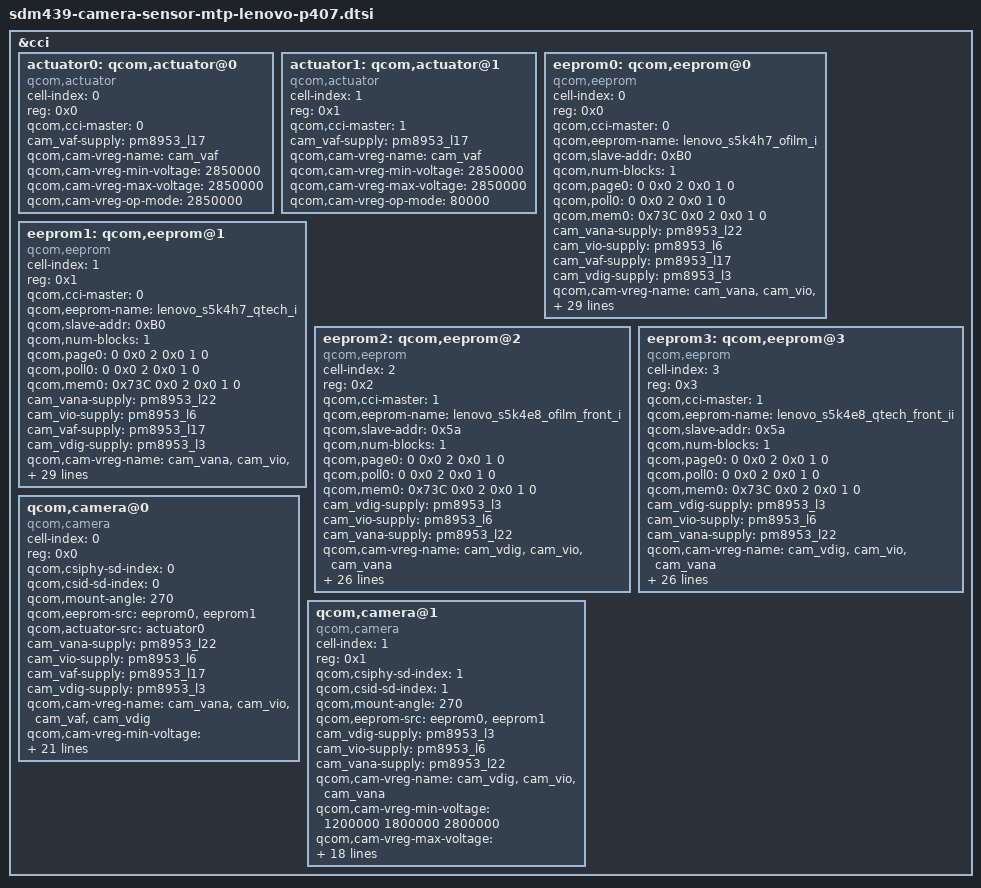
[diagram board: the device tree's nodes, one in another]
/*
 * Copyright (c) 2015-2016, 2018, The Linux Foundation. All rights reserved.
 *
 * This program is free software; you can redistribute it and/or modify
 * it under the terms of the GNU General Public License version 2 and
 * only version 2 as published by the Free Software Foundation.
 *
 * This program is distributed in the hope that it will be useful,
 * but WITHOUT ANY WARRANTY; without even the implied warranty of
 * MERCHANTABILITY or FITNESS FOR A PARTICULAR PURPOSE.  See the
 * GNU General Public License for more details.
 */

#include <dt-bindings/clock/msm-clocks-8952.h>

&cci {
	actuator0: qcom,actuator@0 {
		cell-index = <0>;
		reg = <0x0>;
		compatible = "qcom,actuator";
		qcom,cci-master = <0>;
		cam_vaf-supply = <&pm8953_l17>;
		qcom,cam-vreg-name = "cam_vaf";
		qcom,cam-vreg-min-voltage = <2850000>;
		qcom,cam-vreg-max-voltage = <2850000>;
		qcom,cam-vreg-op-mode = <2850000>;
	};

	actuator1: qcom,actuator@1 {
		cell-index = <1>;
		reg = <0x1>;
		compatible = "qcom,actuator";
		qcom,cci-master = <1>;
		cam_vaf-supply = <&pm8953_l17>;
		qcom,cam-vreg-name = "cam_vaf";
		qcom,cam-vreg-min-voltage = <2850000>;
		qcom,cam-vreg-max-voltage = <2850000>;
		qcom,cam-vreg-op-mode = <80000>;
	};

	eeprom0: qcom,eeprom@0 {
		cell-index = <0>;
		reg = <0x0>;
		compatible = "qcom,eeprom";
		qcom,cci-master = <0>;
		qcom,eeprom-name = "lenovo_s5k4h7_ofilm_i";
		qcom,slave-addr = <0xB0>;
		qcom,num-blocks = <1>;
		
		qcom,page0 = <0 0x0 2 0x0 1 0>;
		qcom,poll0 = <0 0x0 2 0x0 1 0>;
		qcom,mem0 = <0x73C 0x0 2 0x0 1 0>;
		cam_vana-supply = <&pm8953_l22>;
		cam_vio-supply = <&pm8953_l6>;
		cam_vaf-supply = <&pm8953_l17>;
		cam_vdig-supply = <&pm8953_l3>;
		qcom,cam-vreg-name = "cam_vana",
			"cam_vio", "cam_vaf", "cam_vdig";
		qcom,cam-vreg-min-voltage = <2800000 1800000 2850000 1200000>;
		qcom,cam-vreg-max-voltage = <2800000 1800000 2850000 1200000>;
		qcom,cam-vreg-op-mode = <280000 1800000 2850000 1200000>;
		pinctrl-names = "cam_default", "cam_suspend";
		pinctrl-0 = <&cam_sensor_mclk0_default
						&cam_sensor_rear_reset>;
		pinctrl-1 = <&cam_sensor_mclk0_sleep
						&cam_sensor_rear_reset_sleep>;
		gpios = <&tlmm 26 0>,
			<&tlmm 132 0>;
		qcom,gpio-reset = <1>;
		qcom,gpio-req-tbl-num = <0 1>;
		qcom,gpio-req-tbl-flags = <1 0>;
		qcom,gpio-req-tbl-label = "CAMIF_MCLK0",
			"CAM_RESET0";
		qcom,cam-power-seq-type = "sensor_gpio" ,"sensor_vreg", "sensor_vreg",
			"sensor_vreg", "sensor_vreg", "sensor_clk", "sensor_gpio";
		qcom,cam-power-seq-val = "sensor_gpio_reset", "cam_vio", "cam_vana", 
			"cam_vdig", "cam_vaf", "sensor_cam_mclk", "sensor_gpio_reset";
		qcom,cam-power-seq-cfg-val = <0 1 1 1 1 24000000 1>;
		qcom,cam-power-seq-delay = <1 1 1 1 1 1 2>;			
		status = "ok";
		clocks = <&clock_gcc clk_mclk0_clk_src>,
			<&clock_gcc clk_gcc_camss_mclk0_clk>;
		clock-names = "cam_src_clk", "cam_clk";
		qcom,clock-rates = <19200000 0>;
	};

	eeprom1: qcom,eeprom@1 {
		cell-index = <1>;
		reg = <0x1>;
		compatible = "qcom,eeprom";
		qcom,cci-master = <0>;
		qcom,eeprom-name = "lenovo_s5k4h7_qtech_i";
		qcom,slave-addr = <0xB0>;
		qcom,num-blocks = <1>;
		
		qcom,page0 = <0 0x0 2 0x0 1 0>;
		qcom,poll0 = <0 0x0 2 0x0 1 0>;
		qcom,mem0 = <0x73C 0x0 2 0x0 1 0>;
		cam_vana-supply = <&pm8953_l22>;
		cam_vio-supply = <&pm8953_l6>;
		cam_vaf-supply = <&pm8953_l17>;
		cam_vdig-supply = <&pm8953_l3>;
		qcom,cam-vreg-name = "cam_vana",
			"cam_vio", "cam_vaf", "cam_vdig";
		qcom,cam-vreg-min-voltage = <2800000 1800000 2850000 1200000>;
		qcom,cam-vreg-max-voltage = <2800000 1800000 2850000 1200000>;
		qcom,cam-vreg-op-mode = <280000 1800000 2850000 1200000>;
		pinctrl-names = "cam_default", "cam_suspend";
		pinctrl-0 = <&cam_sensor_mclk0_default
						&cam_sensor_rear_reset>;
		pinctrl-1 = <&cam_sensor_mclk0_sleep
						&cam_sensor_rear_reset_sleep>;
		gpios = <&tlmm 26 0>,
			<&tlmm 132 0>;
		qcom,gpio-reset = <1>;
		qcom,gpio-req-tbl-num = <0 1>;
		qcom,gpio-req-tbl-flags = <1 0>;
		qcom,gpio-req-tbl-label = "CAMIF_MCLK0",
			"CAM_RESET0";
		qcom,cam-power-seq-type = "sensor_gpio" ,"sensor_vreg", "sensor_vreg",
			"sensor_vreg", "sensor_vreg", "sensor_clk", "sensor_gpio";
		qcom,cam-power-seq-val = "sensor_gpio_reset", "cam_vio", "cam_vdig", 
			"cam_vana", "cam_vaf", "sensor_cam_mclk", "sensor_gpio_reset";
		qcom,cam-power-seq-cfg-val = <0 1 1 1 1 24000000 1>;
		qcom,cam-power-seq-delay = <1 1 1 1 1 1 2>;			
		status = "ok";
		clocks = <&clock_gcc clk_mclk0_clk_src>,
			<&clock_gcc clk_gcc_camss_mclk0_clk>;
		clock-names = "cam_src_clk", "cam_clk";
		qcom,clock-rates = <19200000 0>;
	};	

//start add front camera by chenbaicheng 20190124
	eeprom2: qcom,eeprom@2 {
		cell-index = <2>;
		reg = <0x2>;
		compatible = "qcom,eeprom";
		qcom,cci-master = <1>;
		qcom,eeprom-name = "lenovo_s5k4e8_ofilm_front_i";
		qcom,slave-addr = <0x5a>;
		qcom,num-blocks = <1>;
		
		qcom,page0 = <0 0x0 2 0x0 1 0>;
		qcom,poll0 = <0 0x0 2 0x0 1 0>;
		qcom,mem0 = <0x73C 0x0 2 0x0 1 0>;

		cam_vdig-supply = <&pm8953_l3>;
		cam_vio-supply = <&pm8953_l6>;
		cam_vana-supply = <&pm8953_l22>;
		qcom,cam-vreg-name = "cam_vdig", "cam_vio", "cam_vana";
		qcom,cam-vreg-min-voltage = <1200000 1800000 2800000>;
		qcom,cam-vreg-max-voltage = <1200000 1800000 2800000>;
		qcom,cam-vreg-op-mode = <200000 0 80000>;
		pinctrl-names = "cam_default", "cam_suspend";
		pinctrl-0 = <&cam_sensor_mclk1_default
				&cam_sensor_front_default>;
		pinctrl-1 = <&cam_sensor_mclk1_sleep
				&cam_sensor_front_sleep>;
		gpios = <&tlmm 27 0>,
			<&tlmm 38 0>;
		qcom,gpio-reset = <1>;
		qcom,gpio-req-tbl-num = <0 1>;
		qcom,gpio-req-tbl-flags = <1 0>;
		qcom,gpio-req-tbl-label = "CAMIF_MCLK1",
			"CAM_RESET1";
		qcom,cam-power-seq-type = "sensor_gpio" ,"sensor_vreg", "sensor_vreg",
			"sensor_vreg", "sensor_clk", "sensor_gpio";
		qcom,cam-power-seq-val = "sensor_gpio_reset", "cam_vio", "cam_vdig", 
			"cam_vana", "sensor_cam_mclk", "sensor_gpio_reset";
		qcom,cam-power-seq-cfg-val = <0 1 1 1 24000000 1>;
		qcom,cam-power-seq-delay = <1 5 5 5 1 10>;			
		status = "ok";
		clocks = <&clock_gcc clk_mclk1_clk_src>,
			<&clock_gcc clk_gcc_camss_mclk1_clk>;
		clock-names = "cam_src_clk", "cam_clk";
		qcom,clock-rates = <24000000 0>;
	};

	eeprom3: qcom,eeprom@3 {
		cell-index = <3>;
		reg = <0x3>;
		compatible = "qcom,eeprom";
		qcom,cci-master = <1>;
		qcom,eeprom-name = "lenovo_s5k4e8_qtech_front_ii";
		qcom,slave-addr = <0x5a>;
		qcom,num-blocks = <1>;
		
		qcom,page0 = <0 0x0 2 0x0 1 0>;
		qcom,poll0 = <0 0x0 2 0x0 1 0>;
		qcom,mem0 = <0x73C 0x0 2 0x0 1 0>;

		cam_vdig-supply = <&pm8953_l3>;
		cam_vio-supply = <&pm8953_l6>;
		cam_vana-supply = <&pm8953_l22>;
		qcom,cam-vreg-name = "cam_vdig", "cam_vio", "cam_vana";
		qcom,cam-vreg-min-voltage = <1200000 1800000 2800000>;
		qcom,cam-vreg-max-voltage = <1200000 1800000 2800000>;
		qcom,cam-vreg-op-mode = <200000 0 80000>;
		pinctrl-names = "cam_default", "cam_suspend";
		pinctrl-0 = <&cam_sensor_mclk1_default
				&cam_sensor_front_default>;
		pinctrl-1 = <&cam_sensor_mclk1_sleep
				&cam_sensor_front_sleep>;
		gpios = <&tlmm 27 0>,
			<&tlmm 38 0>;
		qcom,gpio-reset = <1>;
		qcom,gpio-req-tbl-num = <0 1>;
		qcom,gpio-req-tbl-flags = <1 0>;
		qcom,gpio-req-tbl-label = "CAMIF_MCLK1",
			"CAM_RESET1";
		qcom,cam-power-seq-type = "sensor_gpio" ,"sensor_vreg", "sensor_vreg",
			"sensor_vreg", "sensor_clk", "sensor_gpio";
		qcom,cam-power-seq-val = "sensor_gpio_reset", "cam_vio", "cam_vdig", 
			"cam_vana", "sensor_cam_mclk", "sensor_gpio_reset";
		qcom,cam-power-seq-cfg-val = <0 1 1 1 24000000 1>;
		qcom,cam-power-seq-delay = <1 5 5 5 1 10>;			
		status = "ok";
		clocks = <&clock_gcc clk_mclk1_clk_src>,
			<&clock_gcc clk_gcc_camss_mclk1_clk>;
		clock-names = "cam_src_clk", "cam_clk";
		qcom,clock-rates = <24000000 0>;
	};
//end add front camera by chenbaicheng 20190124

	qcom,camera@0 {
		cell-index = <0>;
		compatible = "qcom,camera";
		reg = <0x0>;
		qcom,csiphy-sd-index = <0>;
		qcom,csid-sd-index = <0>;
		qcom,mount-angle = <270>;
//		qcom,led-flash-src = <&led_flash0>;
		qcom,eeprom-src = <&eeprom0 &eeprom1>;
		qcom,actuator-src = <&actuator0>;
		cam_vana-supply = <&pm8953_l22>;
		cam_vio-supply = <&pm8953_l6>;
		cam_vaf-supply = <&pm8953_l17>;
		cam_vdig-supply = <&pm8953_l3>;
		qcom,cam-vreg-name = "cam_vana",
			"cam_vio", "cam_vaf", "cam_vdig";
		qcom,cam-vreg-min-voltage = <2800000 1800000 2850000 1200000>;
		qcom,cam-vreg-max-voltage = <2800000 1800000 2850000 1200000>;
		qcom,cam-vreg-op-mode = <2800000 1800000 2850000 1200000>;
		pinctrl-names = "cam_default", "cam_suspend";
		pinctrl-0 = <&cam_sensor_mclk0_default
				&cam_sensor_rear_reset>;
		pinctrl-1 = <&cam_sensor_mclk0_sleep
				&cam_sensor_rear_reset_sleep>;
		gpios = <&tlmm 26 0>,
			<&tlmm 132 0>;
		qcom,gpio-reset = <1>;
		qcom,gpio-req-tbl-num = <0 1>;
		qcom,gpio-req-tbl-flags = <1 0>;
		qcom,gpio-req-tbl-label = "CAMIF_MCLK0",
			"CAM_RESET0";
		qcom,sensor-position = <0>;
		qcom,sensor-mode = <0>;
		qcom,cci-master = <0>;
		status = "ok";
		clocks = <&clock_gcc clk_mclk0_clk_src>,
				<&clock_gcc clk_gcc_camss_mclk0_clk>;
		clock-names = "cam_src_clk", "cam_clk";
		qcom,clock-rates = <24000000 0>;
	};

//begin add front camera by chenbaicheng 20190124
	qcom,camera@1 {
		cell-index = <1>;
		compatible = "qcom,camera";
		reg = <0x1>;
		qcom,csiphy-sd-index = <1>;
		qcom,csid-sd-index = <1>;
		qcom,mount-angle = <270>;
		qcom,eeprom-src = <&eeprom0 &eeprom1>;
		cam_vdig-supply = <&pm8953_l3>;
		cam_vio-supply = <&pm8953_l6>;
		cam_vana-supply = <&pm8953_l22>;
		qcom,cam-vreg-name = "cam_vdig", "cam_vio", "cam_vana";
		qcom,cam-vreg-min-voltage = <1200000 1800000 2800000>;
		qcom,cam-vreg-max-voltage = <1200000 1800000 2800000>;
		qcom,cam-vreg-op-mode = <200000 0 80000>;
		pinctrl-names = "cam_default", "cam_suspend";
		pinctrl-0 = <&cam_sensor_mclk1_default
				&cam_sensor_front_default>;
		pinctrl-1 = <&cam_sensor_mclk1_sleep
				&cam_sensor_front_sleep>;
		gpios = <&tlmm 27 0>,
			<&tlmm 38 0>;
		qcom,gpio-reset = <1>;
		qcom,gpio-req-tbl-num = <0 1>;
		qcom,gpio-req-tbl-flags = <1 0>;
		qcom,gpio-req-tbl-label = "CAMIF_MCLK1",
			"CAM_RESET1";
		qcom,sensor-position = <0x100>;
		qcom,sensor-mode = <1>;
		qcom,cci-master = <1>;
		clocks = <&clock_gcc clk_mclk1_clk_src>,
				<&clock_gcc clk_gcc_camss_mclk1_clk>;
		clock-names = "cam_src_clk", "cam_clk";
		qcom,clock-rates = <24000000 0>;
	};
//end add front camera by chenbaicheng 20190124

};
